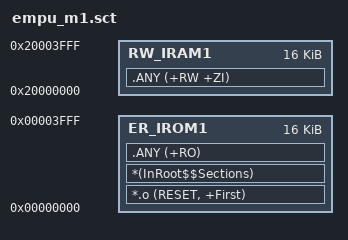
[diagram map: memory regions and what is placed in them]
; *************************************************************
; *** Scatter-Loading Description File generated by uVision ***
; *************************************************************

LR_IROM1 0x00000000 0x00004000  {    ; load region size_region (16KB)
  ER_IROM1 0x00000000 0x00004000  {  ; load address = execution address
   *.o (RESET, +First)
   *(InRoot$$Sections)
   .ANY (+RO)
  }
  RW_IRAM1 0x20000000 0x00004000  {  ; RW data (16KB)
   .ANY (+RW +ZI)
  }
}

